VERSION ""

NS_ :

BS_:

BU_: XXX

BO_ 482 EPS: 8 XXX
 SG_ SteeringAngle : 0|16@1- (0.1,0) [-3276.8|3276.7] "deg" XXX
 SG_ SteeringAngleRate : 16|16@1- (1,0) [-32768|32767] "deg/s" XXX

BO_ 496 CARSPEED: 8 XXX
 SG_ CarDisplaySpeed : 0|16@1+ (1,0) [0|65535] "" XXX

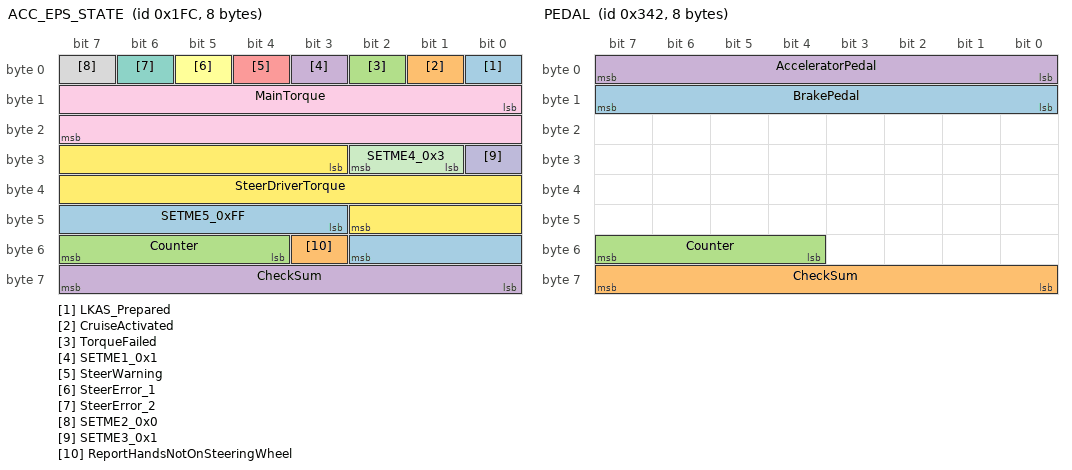
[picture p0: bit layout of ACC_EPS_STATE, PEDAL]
BO_ 508 ACC_EPS_STATE: 8 XXX
 SG_ LKAS_Prepared : 0|1@1+ (1,0) [0|1] "" XXX
 SG_ CruiseActivated : 1|1@1+ (1,0) [0|1] "" XXX
 SG_ TorqueFailed : 2|1@1+ (1,0) [0|1] "" XXX
 SG_ SETME1_0x1 : 3|1@1+ (1,0) [0|1] "" XXX
 SG_ SteerWarning : 4|1@1+ (1,0) [0|1] "" XXX
 SG_ SteerError_1 : 5|1@1+ (1,0) [0|1] "" XXX
 SG_ SteerError_2 : 6|1@1+ (1,0) [0|1] "" XXX
 SG_ SETME2_0x0 : 7|1@1+ (1,0) [0|1] "" XXX
 SG_ MainTorque : 8|16@1- (1,0) [-32768|32767] "" XXX
 SG_ SETME3_0x1 : 24|1@1+ (1,0) [0|1] "" XXX
 SG_ SETME4_0x3 : 25|2@1+ (1,0) [0|3] "" XXX
 SG_ SteerDriverTorque : 27|16@1- (1,0) [-32768|32767] "" XXX
 SG_ SETME5_0xFF : 43|8@1+ (1,0) [0|255] "" XXX
 SG_ ReportHandsNotOnSteeringWheel : 51|1@1+ (1,0) [0|1] "" XXX
 SG_ Counter : 52|4@1+ (1,0) [0|15] "" XXX
 SG_ CheckSum : 56|8@1+ (1,0) [0|255] "" XXX

BO_ 834 PEDAL: 8 XXX
 SG_ BrakePedal : 8|8@1+ (0.01,0) [0|255] "" XXX
 SG_ CheckSum : 56|8@1+ (1,0) [0|255] "" XXX
 SG_ Counter : 55|4@0+ (1,0) [0|15] "" XXX
 SG_ AcceleratorPedal : 0|8@1+ (0.01,0) [0|255] "" XXX

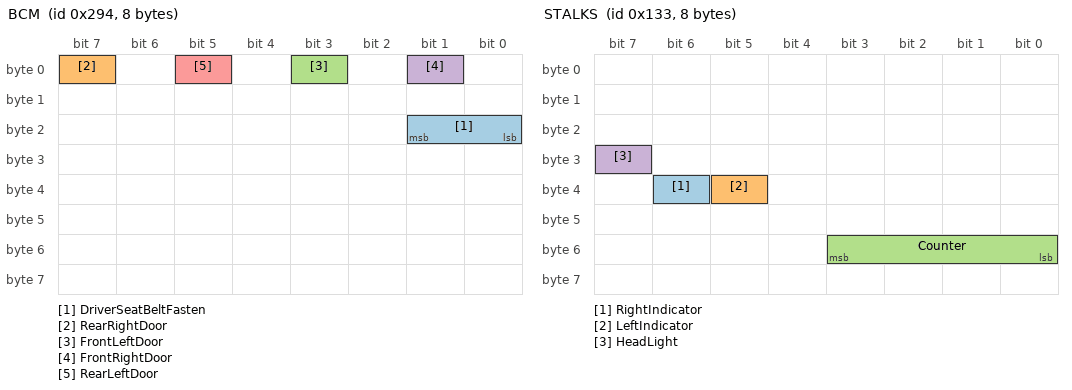
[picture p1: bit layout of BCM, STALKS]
BO_ 660 BCM: 8 XXX
 SG_ DriverSeatBeltFasten : 17|2@0+ (1,0) [0|3] "" XXX
 SG_ RearRightDoor : 7|1@0+ (1,0) [0|1] "" XXX
 SG_ FrontLeftDoor : 3|1@0+ (1,0) [0|1] "" XXX
 SG_ FrontRightDoor : 1|1@1+ (1,0) [0|1] "" XXX
 SG_ RearLeftDoor : 5|1@1+ (1,0) [0|1] "" XXX

BO_ 307 STALKS: 8 XXX
 SG_ RightIndicator : 38|1@0+ (1,0) [0|1] "" XXX
 SG_ LeftIndicator : 37|1@0+ (1,0) [0|1] "" XXX
 SG_ Counter : 48|4@1+ (1,0) [0|15] "" XXX
 SG_ HeadLight : 31|1@0+ (1,0) [0|1] "" XXX

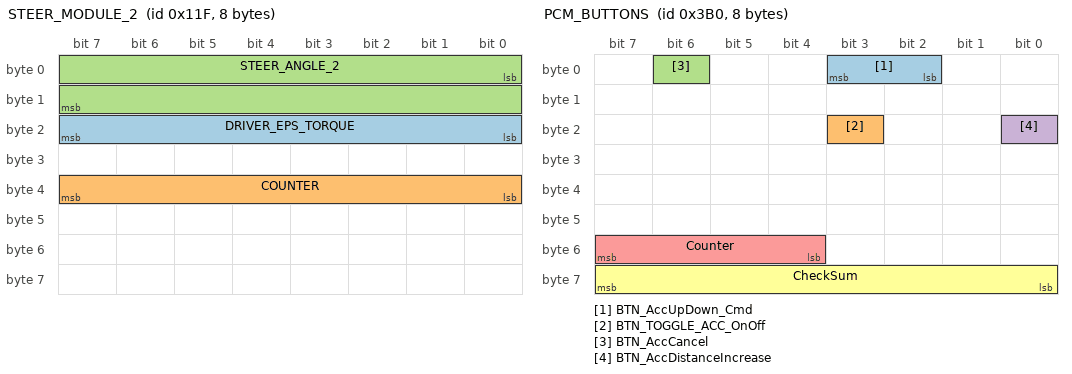
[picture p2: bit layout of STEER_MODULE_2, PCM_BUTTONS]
BO_ 287 STEER_MODULE_2: 8 XXX
 SG_ DRIVER_EPS_TORQUE : 16|8@1+ (1,0) [0|255] "" XXX
 SG_ COUNTER : 39|8@0+ (1,0) [0|255] "" XXX
 SG_ STEER_ANGLE_2 : 0|16@1- (0.1,0) [0|65535] "" XXX

BO_ 944 PCM_BUTTONS: 8 XXX
 SG_ BTN_AccUpDown_Cmd : 3|2@0+ (1,0) [0|3] "" XXX
 SG_ BTN_TOGGLE_ACC_OnOff : 19|1@0+ (1,0) [0|1] "" XXX
 SG_ BTN_AccCancel : 6|1@0+ (1,0) [0|1] "" XXX
 SG_ BTN_AccDistanceIncrease : 16|1@0+ (1,0) [0|1] "" XXX
 SG_ Counter : 55|4@0+ (1,0) [0|15] "" XXX
 SG_ CheckSum : 63|8@0+ (1,0) [0|255] "" XXX

BO_ 544 PEDAL_PRESSED: 8 XXX
 SG_ PEDAL_PRESSED_ACTIVE_LOW : 12|1@0+ (1,0) [0|1] "" XXX

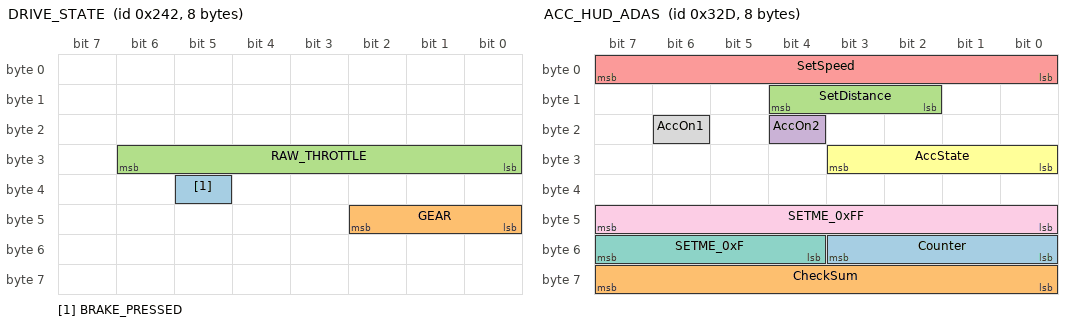
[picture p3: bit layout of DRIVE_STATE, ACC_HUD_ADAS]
BO_ 578 DRIVE_STATE: 8 XXX
 SG_ BRAKE_PRESSED : 37|1@0+ (1,0) [0|1] "" XXX
 SG_ GEAR : 40|3@1+ (1,0) [0|7] "" XXX
 SG_ RAW_THROTTLE : 30|7@0+ (1,0) [0|127] "" XXX

BO_ 813 ACC_HUD_ADAS: 8 XXX
 SG_ Counter : 48|4@1+ (1,0) [0|15] "" XXX
 SG_ CheckSum : 56|8@1+ (1,0) [0|255] "" XXX
 SG_ SetDistance : 12|3@0+ (1,0) [0|7] "" XXX
 SG_ AccOn2 : 20|1@0+ (1,0) [0|1] "" XXX
 SG_ SetSpeed : 0|8@1+ (0.5,0) [0|255] "" XXX
 SG_ AccState : 24|4@1+ (1,0) [0|15] "" XXX
 SG_ SETME_0xF : 55|4@0+ (1,0) [0|15] "" XXX
 SG_ AccOn1 : 22|1@0+ (1,0) [0|1] "" XXX
 SG_ SETME_0xFF : 47|8@0+ (1,0) [0|255] "" XXX

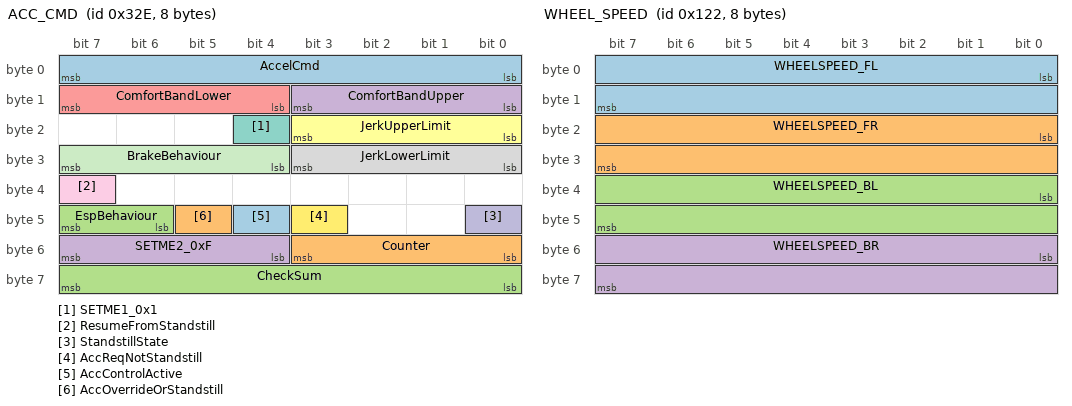
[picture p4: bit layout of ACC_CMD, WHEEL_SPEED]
BO_ 814 ACC_CMD: 8 XXX
 SG_ AccelCmd : 0|8@1+ (1,-100) [0|255] "" XXX
 SG_ Counter : 48|4@1+ (1,0) [0|15] "" XXX
 SG_ CheckSum : 56|8@1+ (1,0) [0|255] "" XXX
 SG_ ComfortBandUpper : 8|4@1+ (1,0) [0|15] "" XXX
 SG_ ComfortBandLower : 12|4@1+ (1,0) [0|15] "" XXX
 SG_ JerkUpperLimit : 16|4@1+ (1,0) [0|15] "" XXX
 SG_ SETME1_0x1 : 20|1@1+ (1,0) [0|1] "" XXX
 SG_ JerkLowerLimit : 24|4@1+ (1,0) [0|15] "" XXX
 SG_ ResumeFromStandstill : 39|1@0+ (1,0) [0|1] "" XXX
 SG_ StandstillState : 40|1@0+ (1,0) [0|1] "" XXX
 SG_ BrakeBehaviour : 28|4@1+ (1,0) [0|15] "" XXX
 SG_ AccReqNotStandstill : 43|1@0+ (1,0) [0|1] "" XXX
 SG_ AccControlActive : 44|1@0+ (1,0) [0|1] "" XXX
 SG_ AccOverrideOrStandstill : 45|1@0+ (1,0) [0|1] "" XXX
 SG_ EspBehaviour : 46|2@1+ (1,0) [0|3] "" XXX
 SG_ SETME2_0xF : 55|4@0+ (1,0) [0|15] "" XXX

BO_ 1048 BSM: 8 XXX
 SG_ LEFT_APPROACH : 23|1@0+ (1,0) [0|1] "" XXX
 SG_ RIGHT_APPROACH : 17|1@0+ (1,0) [0|1] "" XXX

BO_ 290 WHEEL_SPEED: 8 XXX
 SG_ WHEELSPEED_FL : 0|16@1+ (0.1,0) [0|65535] "" XXX
 SG_ WHEELSPEED_FR : 16|16@1+ (0.1,0) [0|65535] "" XXX
 SG_ WHEELSPEED_BL : 32|16@1+ (0.1,0) [0|65535] "" XXX
 SG_ WHEELSPEED_BR : 48|16@1+ (0.1,0) [0|65535] "" XXX

BO_ 790 ACC_MPC_STATE: 8 XXX
 SG_ AutoFullBeamState : 0|2@1+ (1,0) [0|3] "" XXX
 SG_ LeftLaneState : 2|2@1+ (1,0) [0|3] "" XXX
 SG_ LKAS_Config : 4|2@1+ (1,0) [0|3] "" XXX
 SG_ SETME2_0x1 : 6|1@1+ (1,0) [0|1] "" XXX
 SG_ MPC_State : 7|3@1+ (1,0) [0|7] "" XXX
 SG_ AutoFullBeam_OnOff : 10|1@1+ (1,0) [0|1] "" XXX
 SG_ LKAS_Output : 11|16@1- (1,0) [-32768|32767] "" XXX
 SG_ LKAS_Active : 27|1@1+ (1,0) [0|1] "" XXX
 SG_ SETME3_0x0 : 28|1@1+ (1,0) [0|1] "" XXX
 SG_ TrafficSignRecognition_OnOff : 29|1@1+ (1,0) [0|1] "" XXX
 SG_ SETME4_0x0 : 30|1@1+ (1,0) [0|1] "" XXX
 SG_ SETME5_0x1 : 31|1@1+ (1,0) [0|1] "" XXX
 SG_ RightLaneState : 32|2@1+ (1,0) [0|3] "" XXX
 SG_ LKAS_State : 34|2@1+ (1,0) [0|3] "" XXX
 SG_ SETME6_0x0 : 36|1@1+ (1,0) [0|1] "" XXX
 SG_ TrafficSignRecognition_Result : 37|4@1+ (1,0) [0|15] "" XXX
 SG_ LKAS_AlarmType : 41|2@1+ (1,0) [0|3] "" XXX
 SG_ SETME7_0x3 : 43|2@1+ (1,0) [0|3] "" XXX
 SG_ ReqHandsOnSteeringWheel : 45|1@1+ (1,0) [0|1] "" XXX
 SG_ LKAS_ReqPrepare : 46|1@1+ (1,0) [0|1] "" XXX
 SG_ Counter : 48|4@1+ (1,0) [0|15] "" XXX
 SG_ CheckSum : 56|8@1+ (1,0) [0|255] "" XXX

VAL_ 578 GEAR 4 "D" 2 "R" 1 "P" ;
